# PIC18F46Q10 register map
Vendor: Microchip
Architecture 18xxxx. Special function registers and configuration words.
Registers are 8-bit, read-write, reset 0x0 unless marked. A register's access mark holds for its fields unless they carry their own. Addresses are absolute, and some are shared; only a register's first bit layout is shown; lines under a group give offsets from that group; [hi:lo] are bit positions; {n}, {i} and the like mark numbered series; 'fields as' and 'values as' point back to an identical list; <NAME> marks a mode.

## Further device data
pins=1: VPP/MCLR_n/ICD_n/IOCE3/RE3; 2: ANA0/C1IN0-/C2IN0-/IOCA0/RA0; 3: ANA1/C1IN1-/C2IN1-/IOCA1/RA1; 4: DAC1OUT1/VREF-/ANA2/C1IN0+/C2IN0+/IOCA2/RA2; 5: VREF+/ANA3/C1IN1+/IOCA3/RA3; 6: ANA4/IOCA4/RA4; 7: ANA5/IOCA5/RA5; 8: ANE0/RE0; 9: ANE1/RE1; 10: ANE2/RE2; 11: VDD; 12: VSS; 13: CLKIN/OSC1/ANA7/IOCA7/RA7; 14: OSC2/CLKOUT/ANA6/IOCA6/RA6; 15: SOSCO/ANC0/IOCC0/RC0; 16: SOSCI/ANC1/IOCC1/RC1; 17: ANC2/IOCC2/RC2; 18: SMB_I2C/ANC3/IOCC3/RC3; 19: SMB_I2C/AND0/RD0; 20: SMB_I2C/AND1/RD1; 21: AND2/RD2; 22: AND3/RD3; 23: SMB_I2C/ANC4/IOCC4/RC4; 24: ANC5/IOCC5/RC5; 25: ANC6/IOCC6/RC6; 26: ANC7/IOCC7/RC7; 27: AND4/RD4; 28: AND5/RD5; 29: AND6/RD6; 30: AND7/RD7; 31: VSS; 32: AVDD/VDD; 33: ZCD/ANB0/C2IN1+/IOCB0/RB0; 34: ANB1/C1IN3-/C2IN3-/SMB_I2C/IOCB1/RB1; 35: ANB2/SMB_I2C/IOCB2/RB2; 36: ANB3/C1IN2-/C2IN2-/IOCB3/RB3; 37: ANB4/IOCB4/RB4; 38: ANB5/IOCB5/RB5; 39: ICSPCLK/ICDCLK/ANB6/IOCB6/RB6; 40: ICSPDAT/ICDDAT/DAC1OUT2/ANB7/IOCB7/RB7

## cla_clc
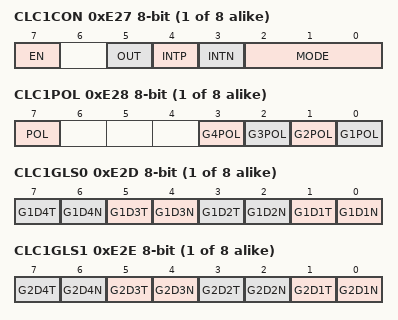
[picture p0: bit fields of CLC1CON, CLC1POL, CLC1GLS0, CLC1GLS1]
{0xE1D+0xA*i} CLC{i}CON (i=1..8) — Configurable logic cell control
  [7] EN, [5] OUT ro, [4] INTP, [3] INTN, [2:0] MODE
{0xE1E+0xA*i} CLC{i}POL reset not defined (i=1..8) — Polarity control (power-on value 0---xxxx)
  [7] POL, [n-1] G{n}POL (n=1..4)
{0xE1F+0xA*i} CLC{i}SEL0 reset not defined (i=1..8) — Input select register 1 (power-on value xxxxxxxx)
  [7:0] D1S
{0xE20+0xA*i} CLC{i}SEL1 reset not defined (i=1..8) — Input select register 1 (power-on value xxxxxxxx)
  [7:0] D2S
{0xE21+0xA*i} CLC{i}SEL2 reset not defined (i=1..8) — Input select register 1 (power-on value xxxxxxxx)
  [7:0] D3S
{0xE22+0xA*i} CLC{i}SEL3 reset not defined (i=1..8) — Input select register 1 (power-on value xxxxxxxx)
  [7:0] D4S
{0xE23+0xA*i} CLC{i}GLS0 reset not defined (i=1..8) — Gate logic select register 0 (power-on value xxxxxxxx)
  [2n-1] G1D{n}T (n=1..4), [2n-2] G1D{n}N (n=1..4)
{0xE24+0xA*i} CLC{i}GLS1 reset not defined (i=1..8) — Gate logic select register 1 (power-on value xxxxxxxx)
  [2n-1] G2D{n}T (n=1..4), [2n-2] G2D{n}N (n=1..4)
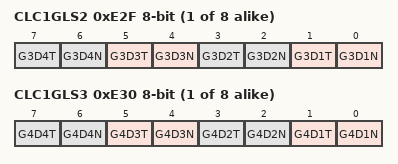
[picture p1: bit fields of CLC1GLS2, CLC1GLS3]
{0xE25+0xA*i} CLC{i}GLS2 reset not defined (i=1..8) — Gate logic select register 2 (power-on value xxxxxxxx)
  [2n-1] G3D{n}T (n=1..4), [2n-2] G3D{n}N (n=1..4)
{0xE26+0xA*i} CLC{i}GLS3 reset not defined (i=1..8) — Gate logic select register 3 (power-on value xxxxxxxx)
  [2n-1] G4D{n}T (n=1..4), [2n-2] G4D{n}N (n=1..4)

## mssp
0xE8D SSP2BUF reset not defined — (power-on value xxxxxxxx)
  [7:0] SSPBUF
0xE8E SSP2ADD
  [7:0] SSPADD
0xE8F SSP2MSK reset 0xFF
  [7:0] SSPMSK
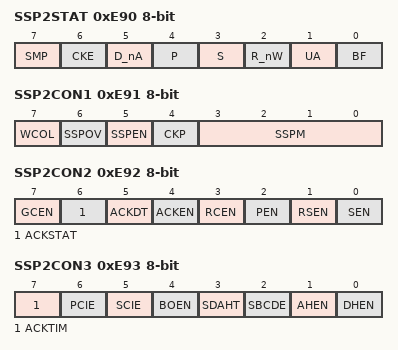
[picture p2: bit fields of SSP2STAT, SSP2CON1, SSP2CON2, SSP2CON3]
0xE90 SSP2STAT — MSSP2 STATUS REGISTER
  [7] SMP — SPI Data Input Sample Phase bit
  [6] CKE — SPI Clock Edge Select bit
  [5] D_nA ro — Data/Address bit
  [4] P ro — Stop bit
  [3] S ro — Start bit
  [2] R_nW ro — Read/Write Information bit
  [1] UA ro — Update Address bit
  [0] BF ro — Buffer Full Status bit (Receive mode only)
0xE91 SSP2CON1
  [7] WCOL — Write Collision Detect bit (Transmit mode only)
  [6] SSPOV — Receive Overflow Indicator bit
  [5] SSPEN — Synchronous Serial Port Enable bit
  [4] CKP — Clock Polarity Select bit
  [3:0] SSPM — Synchronous Serial Port Mode Select bits
0xE92 SSP2CON2
  [7] GCEN — General Call Enable bit (Slave mode only)
  [6] ACKSTAT ro — Acknowledge Status bit (Transmission only)
  [5] ACKDT — Acknowledge Data bit (Receive mode only)
  [4] ACKEN — Acknowledge Sequence Enable bit (Master Receive mode only)
  [3] RCEN — Receive Enable bit (Master mode only)
  [2] PEN — Stop Condition Enable bit (Master mode only)
  [1] RSEN — Repeated Start Condition Enable bit (Master mode only)
  [0] SEN — Start Condition Enable/Stretch Enable bit
0xE93 SSP2CON3
  [7] ACKTIM ro, [6] PCIE, [5] SCIE, [4] BOEN, [3] SDAHT, [2] SBCDE, [1] AHEN, [0] DHEN
0xF91 SSP1BUF reset not defined — (power-on value xxxxxxxx)
  [7:0] SSPBUF
0xF92 SSP1ADD
  [7:0] SSPADD
0xF93 SSP1MSK reset 0xFF
  [7:0] SSPMSK
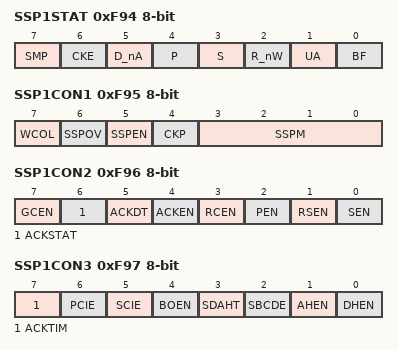
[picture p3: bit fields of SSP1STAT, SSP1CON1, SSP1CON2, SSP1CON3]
0xF94 SSP1STAT — MSSP1 STATUS REGISTER
  fields as SSP2STAT
0xF95 SSP1CON1
  fields as SSP2CON1
0xF96 SSP1CON2
  fields as SSP2CON2
0xF97 SSP1CON3
  fields as SSP2CON3
